# MIK32 register map
Vendor: Mikron; Series: MIK32; File version: 1.0
Registers are 32-bit, read-write, reset 0x0 unless marked. A register's access mark holds for its fields unless they carry their own. Offsets are from the block's base; [hi:lo] are bit positions; {n}, {i} and the like mark numbered series.

## OTP — Контроллер блока однократно-программируемой памяти
Base 0x00051400
0x00 OTPDAT — Регистр чтения/записи данных
  [31:0] DATA — Сразу после выполнения записи в этот регистр будет запущена внутренняя процедура записи загруженных данных в массив antifuse OTP. Временные параметры данной операции могут быть настроены с помощью других регистров. При чтении из этого регистра считываются данные, полученные из OTP
0x04 OTPA — Регистр адреса страницы
  [4:0] ADDR — Адрес слова для выполнения записи/чтения.
    {v}=Main_array{v+1} (Номер строки основного массива OTP) (v=0..3); {v}=Test_row{v-3} (Тестовая строка OTP) (v=4..7); {v}=Test_column{v-7} (Тестовый столбец OTP) (v=8..11); {v}=Test_bit{v-11} (Тестовый бит) (v=12..15)
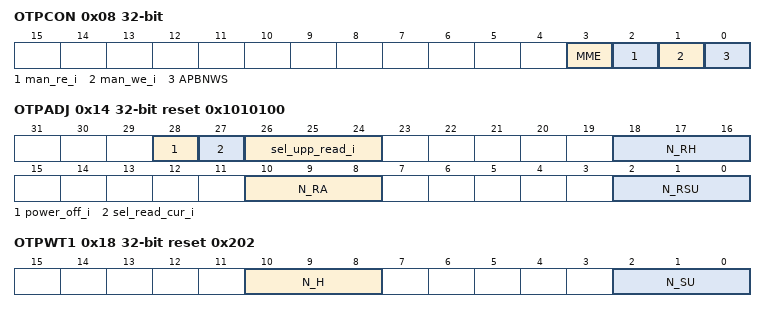
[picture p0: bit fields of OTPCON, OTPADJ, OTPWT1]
0x08 OTPCON wo — Регистр управления
  [3] MME — Режим ручного управления включен. В этом режиме автоматизированные операции чтения и записи не выполняются. Используется для тестирования
  [2] man_re_i — Ручное управление сигналом re i блока Hard IP. Используется для тестирования
  [1] man_we_i — Ручное управление сигналом we i блока Hard IP. Используется для тестирования
  [0] APBNWS — Отключение вставки тактов ожидания в процессе обмена по APB при чтении данных (обращении к регистру OTPDAT на чтение). Если такты ожидания отключены (APBNWS=1), то требуется производить опрос флага OTPSTA.BSY после записи адреса в OTPA до тех пор, пока EESTA.BSY не станет равным 0
0x0C OTPSTA ro — Регистр статуса
  [0] BSY — Блок занят (выполняется запрошенная операция)
    0=Ready (Блок готов); 1=Busy (Блок занят)
0x10 OTPDEC ro — Регистр дешифратора строк
  [8:0] DECO — Выход дешифратора строк блока OTP. Используется для тестирования. Проверка функционирования дешифратора строк осуществляется путем смены адреса тестового столбца, страницы и контроля выходов дешифратора
0x14 OTPADJ reset 0x1010100 — Регистр управления временными параметрами процедуры чтения и доп. настройками
  [28] power_off_i — Режим пониженного энергопотребления. После вывода Hard IP из режима пониженного энергопотребления требуется некоторое время перед тем, как могут быть начаты новые операции
    0=Active_mode (Hard IP выведен из режима пониженного энергопотребления и может выполнять операции чтения и записи); 1=Low_power_mode (Hard IP введен в режим пониженного энергопотребления, операции записи и чтения запрещены)
  [27] sel_read_cur_i — Выбор тока считывания. Используется для тестирования. Не рекомендуется изменять в штатном режиме работы.
    0=2uA (Ток считывания 2мкА); 1=0_2uA (Ток считывания 0,2мкА)
  [26:24] sel_upp_read_i — Выбор напряжения чтения
    0bx00=2V (Напряжения чтения 2,0 В); 0bx01=2_5V (Напряжения чтения 2,5 B); 0bx11=3V (Напряжения чтения 3,0 B); 2=VDD18 (Напряжения чтения VDD18); 6=VDD5 (Напряжения чтения VDD5)
  [18:16] N_RH — Время между задним фронтом re_i и моментом, в который может быть начата новая транзакция на APB. Должно использоваться для обеспечения требования к временам удержания Hard IP. Рекомендуемое значение N_RH = =ceil(40/Pclk), где Pclk – период тактового сигнала в нс, ceil – функция округления до ближайшего большего целого числа. Пример: два такта для частоты Fclk = 33,3 МГц. Для корректной работы схемы значение должно быть больше 0
  [10:8] N_RA — Длительность высокого уровня сигнала re_i (вход Hard IP) в тактах. Рекомендуемое значение N_RA = ceil(40/Pclk), где Pclk – период тактового сигнала в ceil – функция округления до ближайшего большего целого числа. Пример: два такта для частоты Fclk = 33,3 МГц. Для корректной работы схемы значение должно быть больше 0
  [2:0] N_RSU — Время между моментом начала транзакции на APB и положительным фронтом re i в тактах. Должно использоваться для обеспечения требования к временам предустановки Hard IP. Учитывая то, что на входе i удерживаются стабильные уровни в результате предыдущей операции записи в регистр OTPA, при частотах ниже 200 МГц данное значение рекомендуется устанавливать равным 0
0x18 OTPWT1 reset 0x202 — Регистр подстройки длительности процедуры записи 1
  [10:8] N_H — Время между задним фронтом we_i и задним фронтом OTPSTA.BSY в тактах. Должно использоваться для обеспечения требования к временам удержания Hard IP. Рекомендуемое значение N_H=ceil(40/Pclk), где Pclk – период тактового сигнала в нс, ceil – функция округления до ближайшего большего целого числа. Пример – ldf такта для частоты Fclk = 33,3 МГц. Для корректной работы схемы значение должно быть больше 0
  [2:0] N_SU — Время между моментом окончания транзакции на APB и положительным фронтом we i в тактах. Должно использоваться для обеспечения требования к временам предустановки Hard IP. Рекомендуемое значение N_SU = =ceil(40/Pclk), где Pclk – период тактового сигнала в нс, ceil – функция округле-ния до ближайшего большего целого числа. Пример – два такта для частоты Fclk = 33,3 МГц. Для корректной работы схемы значение должно быть больше 0
0x1C OTPWT2 reset 0x196E6B — Регистр подстройки длительности процедуры записи 2
  [23:0] N_W — Длительность высокого уровня сигнала we i (вход Hard IP) в тактах. Рекомендуемое значение N_W = 50000000 нс/Pclk, где Pclk – период тактового сигнала в нс. Пример– 1666667 тактов для частоты Fclk = 33,3 МГц
